# ATSAMB11G18A register map
Vendor: Atmel Corp; Series: SAMB11; File version: TODO
CPU: CM0 r0p0, little endian, no MPU, no FPU, 2 interrupt priority bits
Address unit: 32 bits
Registers are 32-bit, read-write, reset 0x0 unless marked. A register's access mark holds for its fields unless they carry their own. Offsets are from the block's base; [hi:lo] are bit positions.

## SPI0 — SPI Master/Slave Controller
Base 0x40006000
Same registers: SPI1 0x40007000
0x00 TRANSMIT_DATA 8-bit wo — Writes one byte to SPI Transmit Data FIFO.
  [7:0] TX_BYTE — Writes data in transmit FIFO.
0x04 RECEIVE_DATA 8-bit ro — Read one byte from SPI Receive Data FIFO.
  [7:0] RX_BYTE — Oldest data in receive FIFO.
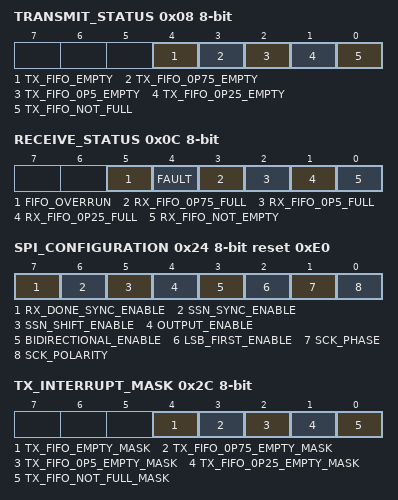
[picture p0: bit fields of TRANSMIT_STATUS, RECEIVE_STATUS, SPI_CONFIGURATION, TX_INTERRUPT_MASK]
0x08 TRANSMIT_STATUS 8-bit ro — Status of the SPI transmitter. Each field can generate an interrupt if corresponding bit in the Tx interrupt mask register is set.
  [4] TX_FIFO_EMPTY — Active High indication when Tx FIFO is Empty and has no more character to transmit
  [3] TX_FIFO_0P75_EMPTY — Active High indication when Tx FIFO is at least three quarters empty. Reset when more.
  [2] TX_FIFO_0P5_EMPTY — Active High indication when Tx FIFO is at least half empty. Reset when more.
  [1] TX_FIFO_0P25_EMPTY — Active High indication when Tx FIFO is at least quarter empty. Reset when more.
  [0] TX_FIFO_NOT_FULL — Active High indication when Tx FIFO can still accepts at least one more character.
    0=TX FIFO Full; 1=TX FIFO not Full
0x0C RECEIVE_STATUS 8-bit ro — Status of the SPI receiver. Each field can generate an interrupt if corresponding bit in the Rx interrupt mask register is set.
  [5] FIFO_OVERRUN — Active High indication when character is received but FIFO is full. Reset by reading the status register.
  [4] FAULT — Active High indication when two masters attempt to access the SPI bus at the same time. The SPI interface will put itself in slave mode in this case. This bit is reset when the status register is read.
  [3] RX_FIFO_0P75_FULL — Active High indication when FIFO is at least three quarters full. Reset when less.
  [2] RX_FIFO_0P5_FULL — Active High indication when FIFO is at least half full. Reset when less.
  [1] RX_FIFO_0P25_FULL — Active High indication when FIFO is at least quarter full. Reset when less.
  [0] RX_FIFO_NOT_EMPTY — Active High indication when data is available in Rx FIFO
0x10 CLOCK_SOURCE_SELECT 8-bit
  [1:0] CLOCK — Clock Used to Generate Divided Clock
    0=26 MHz Clock; 1=13 MHz Clock; 2=6.5 MHz Clock; 3=3.25 MHz Clock
0x14 SPI_CLK_DIVIDER 16-bit — Register sets the divide ratio used to generate the sck clock from the module's input clock.
  [15:0] SPI_DIVIDE_RATIO — Clock Divide Ratio. The input clock signal is divided by (n+1) where n is the value set in this field. The minimum division is by 2; a value of 0 is illegal.
0x18 SPI_MODULE_ENABLE 8-bit — SPI Enable
  [0] ENABLE — Enables SPI operation
0x1C SPI_MASTER_MODE 8-bit — SPI Master/Slave Mode. When clear, SPI is in Slave Mode.
  [0] MASTER_ENABLE — Active High SPI Master Mode Enable
    0=SPI Slave; 1=SPI Master
0x20 SPI_FAULT_ENABLE 8-bit — SPI Fault Detection Mode. If set, SPI bus contention will be detected, and the fault bit in the rx_status register will be set, forcing the SPI Module into idle state. When a fault is detected, the current SPI transaction is abandoned and the interface switches to slave mode in the wait state.
  [0] FAULT_ENABLE — Active High SPI Fault Detect Enable
    0=Faults ignored on SPI bus; 1=Faults detected on SPI bus
0x24 SPI_CONFIGURATION 8-bit reset 0xE0 — SPI Operation Configuration Register. This register should not be modified while SPI bus is active, otherwise the SPI Module state shall not be guaranteed.
  [7] RX_DONE_SYNC_ENABLE — Active High rx_done Signal Synchronisation Enable
    0=rx_done internal synchronisation is bypassed; 1=rx_done is internally synchronised before being used
  [6] SSN_SYNC_ENABLE — Active High SSN Signal Synchronisation Enable
    0=SSN internal synchronisation is bypassed; 1=SSN is internally synchronised before being used
  [5] SSN_SHIFT_ENABLE — Active High Shift Enable when SSN signal is asserted
    0=Shift counter is enabled only when ssn is asserted; 1=Shift counter is always enabled
  [4] OUTPUT_ENABLE — Active High Output Enable when in Bidirectional Mode
    0=MISO is an input if in Slave mode. MOSI is an input if in Master mode; 1=MISO is an output if in Slave mode. MOSI is an output if in Master mode
  [3] BIDIRECTIONAL_ENABLE — Enable Bidirectional mode of operation
    0=SPI is unidirectional, Tx and Rx each has dedicated one port; 1=SPI is bidirectional, Tx and Rx share one input/output port (MOSI if Master, MISO if Slave)
  [2] LSB_FIRST_ENABLE — Selects LSB bits to be transmitted first
    0=Data transmitted MSB first; 1=Data transmitted LSB first
  [1] SCK_PHASE — Selects clock edge used for data sampling and launching
    0=Bits are sampled on the first edge and the following bit is output on the next edge; 1=Bits are output on the first edge and are sampled on the following edge
  [0] SCK_POLARITY — Selects the level of sck in Idle State
    0=SCK is Low; 1=SCK is High
0x28 SPI_BUS_STATUS 8-bit ro — Status of SPI bus.
  [0] SPI_ACTIVE — Active High indicatation that the SPI Module is active. While set, SPI configuration should not be modified.
0x2C TX_INTERRUPT_MASK 8-bit — Enable or Disable the generation of interrupts by the tx_status register.
  [4] TX_FIFO_EMPTY_MASK — Active High Enable of tx_fifo_empty interrupt
  [3] TX_FIFO_0P75_EMPTY_MASK — Active High Enable of tx_fifo_0p75_empty interrupt
  [2] TX_FIFO_0P5_EMPTY_MASK — Active High Enable of tx_fifo_0p5_empty interrupt
  [1] TX_FIFO_0P25_EMPTY_MASK — Active High Enable of tx_fifo_0p25_empty interrupt
  [0] TX_FIFO_NOT_FULL_MASK — Active High Enable of tx_fifo_not_full interrupt
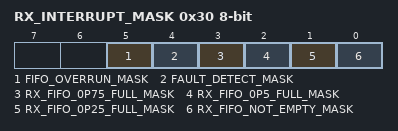
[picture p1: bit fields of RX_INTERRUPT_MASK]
0x30 RX_INTERRUPT_MASK 8-bit — Enable or Disable the generation of interrupts by the rx_status register.
  [5] FIFO_OVERRUN_MASK — Active High Enable of FIFO overrun interrupt
  [4] FAULT_DETECT_MASK — Active High Enable of fault detection interrupt
  [3] RX_FIFO_0P75_FULL_MASK — Active High Enable of rx_fifo_0p75_full interrupt
  [2] RX_FIFO_0P5_FULL_MASK — Active High Enable of rx_fifo_0p5_full interrupt
  [1] RX_FIFO_0P25_FULL_MASK — Active High Enable of rx_fifo_0p25_full interrupt
  [0] RX_FIFO_NOT_EMPTY_MASK — Active High Enable of rx_fifo_not_empty interrupt
